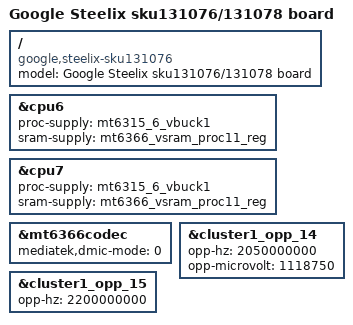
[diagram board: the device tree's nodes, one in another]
// SPDX-License-Identifier: (GPL-2.0 OR MIT)
/*
 * Copyright 2022 Google LLC
 */

/dts-v1/;
#include "mt8186-corsola-steelix.dtsi"
#include "mt6315.dtsi"

/ {
	model = "Google Steelix sku131076/131078 board";
	compatible = "google,steelix-sku131076", "google,steelix-sku131078",
		     "google,steelix", "mediatek,mt8186";
};

&cpu6 {
	proc-supply = <&mt6315_6_vbuck1>;
	sram-supply = <&mt6366_vsram_proc11_reg>;
};

&cpu7 {
	proc-supply = <&mt6315_6_vbuck1>;
	sram-supply = <&mt6366_vsram_proc11_reg>;
};

&mt6366codec {
	mediatek,dmic-mode = <0>; /* two-wire */
};

&cluster1_opp_14 {
	opp-hz = /bits/ 64 <2050000000>;
	opp-microvolt = <1118750>;
};

&cluster1_opp_15 {
	opp-hz = /bits/ 64 <2200000000>;
};
